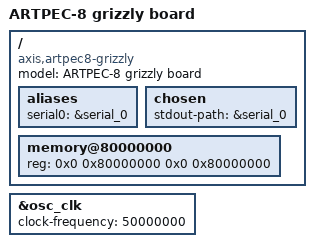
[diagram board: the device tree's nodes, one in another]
// SPDX-License-Identifier: (GPL-2.0 OR MIT)
/*
 * Axis ARTPEC-8 Grizzly board device tree source
 *
 * Copyright (c) 2025 Samsung Electronics Co., Ltd.
 *             https://www.samsung.com
 * Copyright (c) 2025  Axis Communications AB.
 *             https://www.axis.com
 */

/dts-v1/;
#include "artpec8.dtsi"
#include "artpec8-pinctrl.dtsi"
#include <dt-bindings/gpio/gpio.h>
/ {
	model = "ARTPEC-8 grizzly board";
	compatible = "axis,artpec8-grizzly", "axis,artpec8";

	aliases {
		serial0 = &serial_0;
	};

	chosen {
		stdout-path = &serial_0;
	};

	memory@80000000 {
		device_type = "memory";
		reg = <0x0 0x80000000 0x0 0x80000000>;
	};
};

&osc_clk {
	clock-frequency = <50000000>;
};
